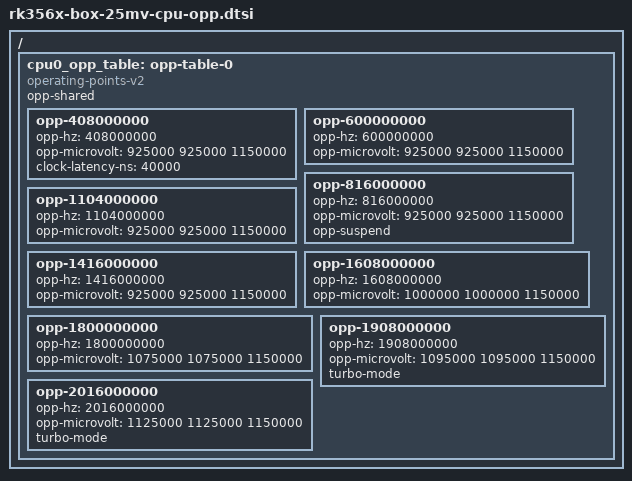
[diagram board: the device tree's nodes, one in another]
// SPDX-License-Identifier: (GPL-2.0+ OR MIT)
// Copyright (C) 2021 hexdump0815

/ {
	cpu0_opp_table: opp-table-0 {
		compatible = "operating-points-v2";
		opp-shared;

		// delete the old nodes coming in from rk356x.dtsi to build everything from scratch
		/delete-node/ opp-480000000;
		/delete-node/ opp-600000000;
		/delete-node/ opp-816000000;
		/delete-node/ opp-1104000000;
		/delete-node/ opp-1416000000;
		/delete-node/ opp-1608000000;
		/delete-node/ opp-1800000000;

		opp-408000000 {
			opp-hz = /bits/ 64 <408000000>;
			opp-microvolt = <925000 925000 1150000>;
			clock-latency-ns = <40000>;
		};

		opp-600000000 {
			opp-hz = /bits/ 64 <600000000>;
			opp-microvolt = <925000 925000 1150000>;
		};

		opp-816000000 {
			opp-hz = /bits/ 64 <816000000>;
			opp-microvolt = <925000 925000 1150000>;
			opp-suspend;
		};

		opp-1104000000 {
			opp-hz = /bits/ 64 <1104000000>;
			opp-microvolt = <925000 925000 1150000>;
		};

		opp-1416000000 {
			opp-hz = /bits/ 64 <1416000000>;
			opp-microvolt = <925000 925000 1150000>;
		};

		opp-1608000000 {
			opp-hz = /bits/ 64 <1608000000>;
			opp-microvolt = <1000000 1000000 1150000>;
		};

		opp-1800000000 {
			opp-hz = /bits/ 64 <1800000000>;
			opp-microvolt = <1075000 1075000 1150000>;
		};

		opp-1908000000 {
			opp-hz = /bits/ 64 <1908000000>;
			opp-microvolt = <1095000 1095000 1150000>;
			turbo-mode;
		};

		opp-2016000000 {
			opp-hz = /bits/ 64 <2016000000>;
			opp-microvolt = <1125000 1125000 1150000>;
			turbo-mode;
		};
	};
};
